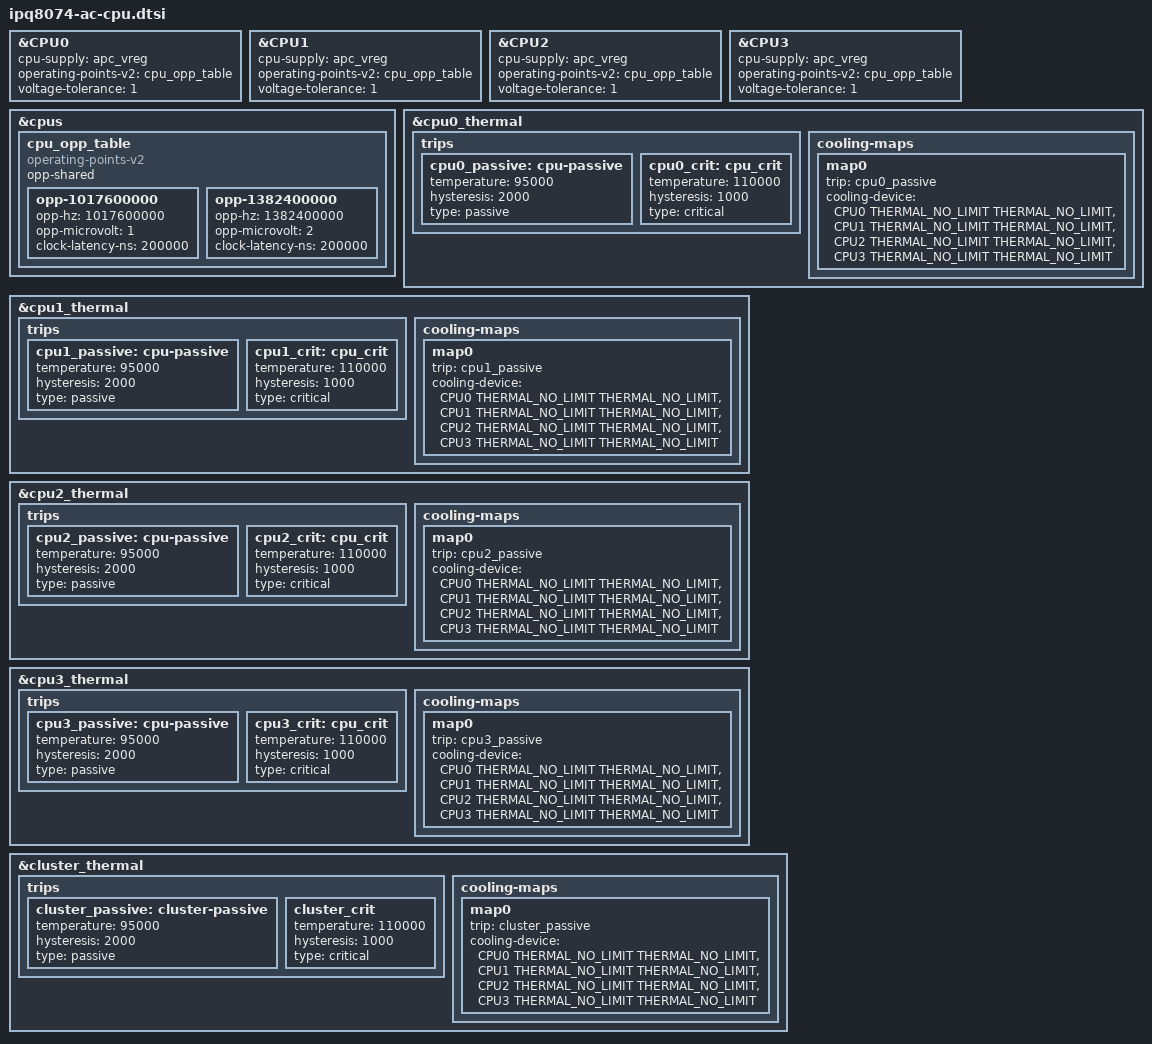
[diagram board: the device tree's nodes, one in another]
// SPDX-License-Identifier: GPL-2.0-only

#include <dt-bindings/thermal/thermal.h>
#include "ipq8074-cpr-regulator.dtsi"

&CPU0 {
	cpu-supply = <&apc_vreg>;
	operating-points-v2 = <&cpu_opp_table>;
	voltage-tolerance = <1>;
};

&CPU1 {
	cpu-supply = <&apc_vreg>;
	operating-points-v2 = <&cpu_opp_table>;
	voltage-tolerance = <1>;
};

&CPU2 {
	cpu-supply = <&apc_vreg>;
	operating-points-v2 = <&cpu_opp_table>;
	voltage-tolerance = <1>;
};

&CPU3 {
	cpu-supply = <&apc_vreg>;
	operating-points-v2 = <&cpu_opp_table>;
	voltage-tolerance = <1>;
};

&cpus {
	cpu_opp_table: cpu_opp_table {
		compatible = "operating-points-v2";
		opp-shared;

		opp-1017600000 {
			opp-hz = /bits/ 64 <1017600000>;
			opp-microvolt = <1>;
			clock-latency-ns = <200000>;
		};
		opp-1382400000 {
			opp-hz = /bits/ 64 <1382400000>;
			opp-microvolt = <2>;
			clock-latency-ns = <200000>;
		};
	};
};

&cpu0_thermal {
	trips {
		cpu0_passive: cpu-passive {
			temperature = <95000>;
			hysteresis = <2000>;
			type = "passive";
		};

		cpu0_crit: cpu_crit {
			temperature = <110000>;
			hysteresis = <1000>;
			type = "critical";
		};
	};

	cooling-maps {
		map0 {
			trip = <&cpu0_passive>;
			cooling-device = <&CPU0 THERMAL_NO_LIMIT THERMAL_NO_LIMIT>,
					 <&CPU1 THERMAL_NO_LIMIT THERMAL_NO_LIMIT>,
					 <&CPU2 THERMAL_NO_LIMIT THERMAL_NO_LIMIT>,
					 <&CPU3 THERMAL_NO_LIMIT THERMAL_NO_LIMIT>;
		};
	};
};

&cpu1_thermal {
	trips {
		cpu1_passive: cpu-passive {
			temperature = <95000>;
			hysteresis = <2000>;
			type = "passive";
		};

		cpu1_crit: cpu_crit {
			temperature = <110000>;
			hysteresis = <1000>;
			type = "critical";
		};
	};

	cooling-maps {
		map0 {
			trip = <&cpu1_passive>;
			cooling-device = <&CPU0 THERMAL_NO_LIMIT THERMAL_NO_LIMIT>,
					 <&CPU1 THERMAL_NO_LIMIT THERMAL_NO_LIMIT>,
					 <&CPU2 THERMAL_NO_LIMIT THERMAL_NO_LIMIT>,
					 <&CPU3 THERMAL_NO_LIMIT THERMAL_NO_LIMIT>;
		};
	};
};

&cpu2_thermal {
	trips {
		cpu2_passive: cpu-passive {
			temperature = <95000>;
			hysteresis = <2000>;
			type = "passive";
		};

		cpu2_crit: cpu_crit {
			temperature = <110000>;
			hysteresis = <1000>;
			type = "critical";
		};
	};

	cooling-maps {
		map0 {
			trip = <&cpu2_passive>;
			cooling-device = <&CPU0 THERMAL_NO_LIMIT THERMAL_NO_LIMIT>,
					 <&CPU1 THERMAL_NO_LIMIT THERMAL_NO_LIMIT>,
					 <&CPU2 THERMAL_NO_LIMIT THERMAL_NO_LIMIT>,
					 <&CPU3 THERMAL_NO_LIMIT THERMAL_NO_LIMIT>;
		};
	};
};

&cpu3_thermal {
	trips {
		cpu3_passive: cpu-passive {
			temperature = <95000>;
			hysteresis = <2000>;
			type = "passive";
		};

		cpu3_crit: cpu_crit {
			temperature = <110000>;
			hysteresis = <1000>;
			type = "critical";
		};
	};

	cooling-maps {
		map0 {
			trip = <&cpu3_passive>;
			cooling-device = <&CPU0 THERMAL_NO_LIMIT THERMAL_NO_LIMIT>,
					 <&CPU1 THERMAL_NO_LIMIT THERMAL_NO_LIMIT>,
					 <&CPU2 THERMAL_NO_LIMIT THERMAL_NO_LIMIT>,
					 <&CPU3 THERMAL_NO_LIMIT THERMAL_NO_LIMIT>;
		};
	};
};

&cluster_thermal {
	trips {
		cluster_passive: cluster-passive {
			temperature = <95000>;
			hysteresis = <2000>;
			type = "passive";
		};

		cluster_crit: cluster_crit {
			temperature = <110000>;
			hysteresis = <1000>;
			type = "critical";
		};
	};

	cooling-maps {
		map0 {
			trip = <&cluster_passive>;
			cooling-device = <&CPU0 THERMAL_NO_LIMIT THERMAL_NO_LIMIT>,
					 <&CPU1 THERMAL_NO_LIMIT THERMAL_NO_LIMIT>,
					 <&CPU2 THERMAL_NO_LIMIT THERMAL_NO_LIMIT>,
					 <&CPU3 THERMAL_NO_LIMIT THERMAL_NO_LIMIT>;
		};
	};
};
